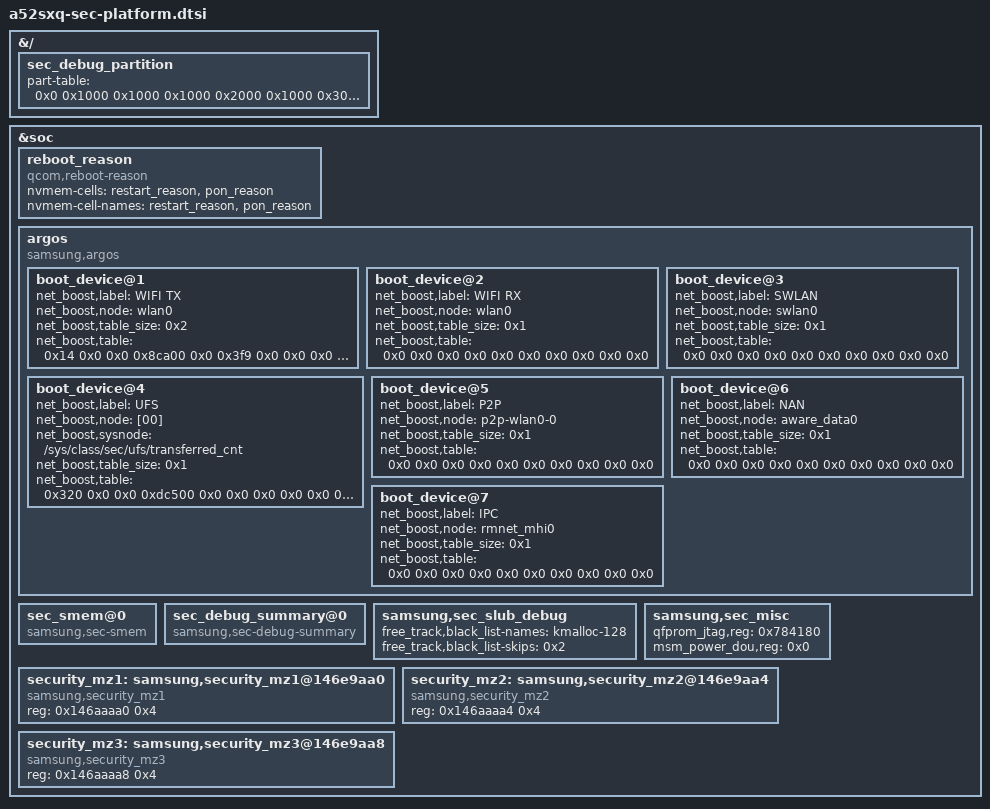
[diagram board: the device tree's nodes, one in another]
// SPDX-License-Identifier: GPL-2.0
/*
 * a52sxq board description for the Qualcomm 6.12 yupik base: sec-platform
 * GENERATED by tools/gen.py from the phone's stock dtbo (5.4 bindings, values verbatim).
 * Do not edit: hand-written 6.12 changes live in a52sxq-bsp612-fixups.dtsi.
 */

&{/} {

	sec_debug_partition {
		part-table = <0x0 0x1000 0x1000 0x1000 0x2000 0x1000 0x3000 0x1000 0x4000 0xa000 0xe000 0x1000 0xf000 0x80000 0x8f000 0x1000 0x90000 0x3000 0x93000 0x1000 0x94000 0x1000 0x95000 0x1000 0xfe000 0x2000 0x100000 0x200000 0x300000 0x200000 0x500000 0x300000>;
	};
};

&soc {

	reboot_reason: reboot_reason {
		compatible = "qcom,reboot-reason";
		nvmem-cells = <&restart_reason &pon_reason>;
		nvmem-cell-names = "restart_reason", "pon_reason";
	};

	argos {
		compatible = "samsung,argos";
		#address-cells = <0x1>;

		boot_device@1 {
			net_boost,label = "WIFI TX";
			net_boost,node = "wlan0";
			net_boost,table_size = <0x2>;
			net_boost,table = <0x14 0x0 0x0 0x8ca00 0x0 0x3f9 0x0 0x0 0x0 0x0 0xc8 0x208500 0x0 0x1b8a00 0x0 0x1429 0x0 0x1 0x1 0x1>;
		};

		boot_device@2 {
			net_boost,label = "WIFI RX";
			net_boost,node = "wlan0";
			net_boost,table_size = <0x1>;
			net_boost,table = <0x0 0x0 0x0 0x0 0x0 0x0 0x0 0x0 0x0 0x0>;
		};

		boot_device@3 {
			net_boost,label = "SWLAN";
			net_boost,node = "swlan0";
			net_boost,table_size = <0x1>;
			net_boost,table = <0x0 0x0 0x0 0x0 0x0 0x0 0x0 0x0 0x0 0x0>;
		};

		boot_device@4 {
			net_boost,label = "UFS";
			net_boost,node = [00];
			net_boost,sysnode = "/sys/class/sec/ufs/transferred_cnt";
			net_boost,table_size = <0x1>;
			net_boost,table = <0x320 0x0 0x0 0xdc500 0x0 0x0 0x0 0x0 0x0 0x0>;
		};

		boot_device@5 {
			net_boost,label = "P2P";
			net_boost,node = "p2p-wlan0-0";
			net_boost,table_size = <0x1>;
			net_boost,table = <0x0 0x0 0x0 0x0 0x0 0x0 0x0 0x0 0x0 0x0>;
		};

		boot_device@6 {
			net_boost,label = "NAN";
			net_boost,node = "aware_data0";
			net_boost,table_size = <0x1>;
			net_boost,table = <0x0 0x0 0x0 0x0 0x0 0x0 0x0 0x0 0x0 0x0>;
		};

		boot_device@7 {
			net_boost,label = "IPC";
			net_boost,node = "rmnet_mhi0";
			net_boost,table_size = <0x1>;
			net_boost,table = <0x0 0x0 0x0 0x0 0x0 0x0 0x0 0x0 0x0 0x0>;
		};
	};

	sec_smem@0 {
		compatible = "samsung,sec-smem";
		status = "okay";
	};

	sec_debug_summary@0 {
		compatible = "samsung,sec-debug-summary";
		status = "okay";
	};

	samsung,sec_slub_debug {
		free_track,black_list-names = "kmalloc-128";
		free_track,black_list-skips = <0x2>;
	};

	samsung,sec_misc {
		qfprom_jtag,reg = <0x784180>;
		msm_power_dou,reg = <0x0>;
	};

	security_mz1: samsung,security_mz1@146e9aa0 {
		compatible = "samsung,security_mz1";
		reg = <0x146aaaa0 0x4>;
	};

	security_mz2: samsung,security_mz2@146e9aa4 {
		compatible = "samsung,security_mz2";
		reg = <0x146aaaa4 0x4>;
	};

	security_mz3: samsung,security_mz3@146e9aa8 {
		compatible = "samsung,security_mz3";
		reg = <0x146aaaa8 0x4>;
	};
};

